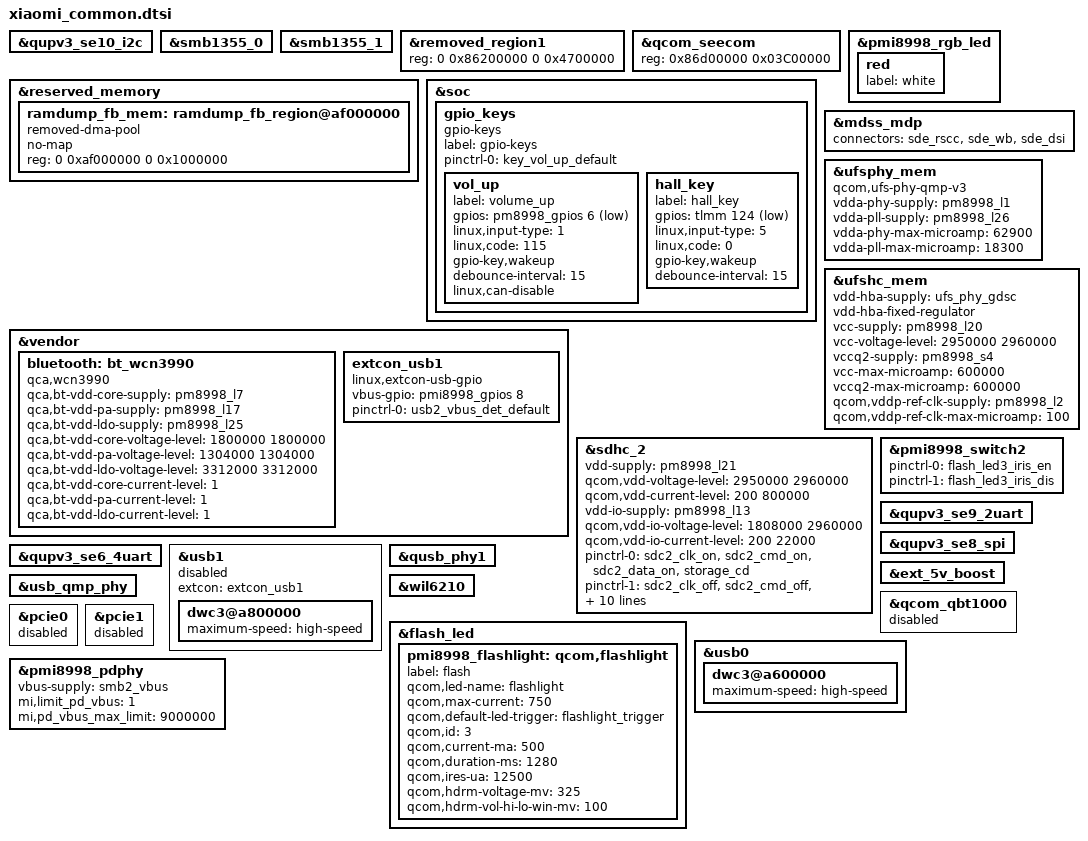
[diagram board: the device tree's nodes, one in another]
/*
 * Common nodes between xiaomi-sdm845 devices
 */

&qupv3_se10_i2c {
	#include "../../qcom/smb1355.dtsi"
};

&smb1355_0 {
	status = "okay";
};

&smb1355_1 {
	status = "okay";
};

&removed_region1 {
	reg = <0 0x86200000 0 0x4700000>;
};

&qcom_seecom {
	reg = <0x86d00000 0x03C00000>;
};

&reserved_memory {
	ramdump_fb_mem: ramdump_fb_region@af000000 {
		compatible = "removed-dma-pool";
		no-map;
		reg = <0 0xaf000000 0 0x1000000>;
	};
};

&soc {
	gpio_keys {
		compatible = "gpio-keys";
		label = "gpio-keys";

		pinctrl-names = "default";
		pinctrl-0 = <&key_vol_up_default>;

		vol_up {
			label = "volume_up";
			gpios = <&pm8998_gpios 6 GPIO_ACTIVE_LOW>;
			linux,input-type = <1>;
			linux,code = <115>;
			gpio-key,wakeup;
			debounce-interval = <15>;
			linux,can-disable;
		};

		hall_key {
			label = "hall_key";
			gpios = <&tlmm 124 GPIO_ACTIVE_LOW>;
			linux,input-type = <5>;
			linux,code = <0>;
			gpio-key,wakeup;
			debounce-interval = <15>;
		};
	};
};

&vendor {
	bluetooth: bt_wcn3990 {
		compatible = "qca,wcn3990";
		qca,bt-vdd-core-supply = <&pm8998_l7>;
		qca,bt-vdd-pa-supply = <&pm8998_l17>;
		qca,bt-vdd-ldo-supply = <&pm8998_l25>;

		qca,bt-vdd-core-voltage-level = <1800000 1800000>;
		qca,bt-vdd-pa-voltage-level = <1304000 1304000>;
		qca,bt-vdd-ldo-voltage-level = <3312000 3312000>;

		qca,bt-vdd-core-current-level = <1>; /* LPM/PFM */
		qca,bt-vdd-pa-current-level = <1>; /* LPM/PFM */
		qca,bt-vdd-ldo-current-level = <1>; /* LPM/PFM */
	};
};

&pmi8998_rgb_led {
	red {
		label = "white";
	};
	/delete-node/ green;
	/delete-node/ blue;
};

&mdss_mdp {
	#cooling-cells = <2>;
	connectors = <&sde_rscc &sde_wb &sde_dsi>;
};

&ufsphy_mem {
	compatible = "qcom,ufs-phy-qmp-v3";

	vdda-phy-supply = <&pm8998_l1>; /* 0.88v */
	vdda-pll-supply = <&pm8998_l26>; /* 1.2v */
	vdda-phy-max-microamp = <62900>;
	vdda-pll-max-microamp = <18300>;

	status = "ok";
};

&ufshc_mem {
	vdd-hba-supply = <&ufs_phy_gdsc>;
	vdd-hba-fixed-regulator;
	vcc-supply = <&pm8998_l20>;
	vcc-voltage-level = <2950000 2960000>;
	vccq2-supply = <&pm8998_s4>;
	vcc-max-microamp = <600000>;
	vccq2-max-microamp = <600000>;

	qcom,vddp-ref-clk-supply = <&pm8998_l2>;
	qcom,vddp-ref-clk-max-microamp = <100>;

	status = "ok";
};

&sdhc_2 {
	vdd-supply = <&pm8998_l21>;
	qcom,vdd-voltage-level = <2950000 2960000>;
	qcom,vdd-current-level = <200 800000>;

	vdd-io-supply = <&pm8998_l13>;
	qcom,vdd-io-voltage-level = <1808000 2960000>;
	qcom,vdd-io-current-level = <200 22000>;

	pinctrl-names = "active", "sleep", "ds_400KHz",
			"ds_50MHz", "ds_100MHz", "ds_200MHz";
	pinctrl-0 = <&sdc2_clk_on  &sdc2_cmd_on &sdc2_data_on &storage_cd>;
	pinctrl-1 = <&sdc2_clk_off &sdc2_cmd_off &sdc2_data_off &storage_cd>;
	pinctrl-2 = <&sdc2_clk_ds_400KHz
			&sdc2_cmd_ds_400KHz &sdc2_data_ds_400KHz>;
	pinctrl-3 = <&sdc2_clk_ds_50MHz
			&sdc2_cmd_ds_50MHz &sdc2_data_ds_50MHz>;
	pinctrl-4 = <&sdc2_clk_ds_100MHz
			&sdc2_cmd_ds_100MHz &sdc2_data_ds_100MHz>;
	pinctrl-5 = <&sdc2_clk_ds_200MHz
			&sdc2_cmd_ds_200MHz &sdc2_data_ds_200MHz>;

	cd-gpios = <&tlmm 126 GPIO_ACTIVE_LOW>;

	status = "ok";
};

&pmi8998_switch2 {
	pinctrl-names = "led_enable", "led_disable";
	pinctrl-0 = <&flash_led3_iris_en>;
	pinctrl-1 = <&flash_led3_iris_dis>;
};

&vendor {
	extcon_usb1: extcon_usb1 {
		compatible = "linux,extcon-usb-gpio";
		vbus-gpio = <&pmi8998_gpios 8 GPIO_ACTIVE_HIGH>;

		pinctrl-names = "default";
		pinctrl-0 = <&usb2_vbus_det_default>;
	};
};

&qupv3_se9_2uart {
	status = "ok";
};

&qupv3_se8_spi {
	status = "ok";
};

&qupv3_se6_4uart {
	status = "ok";
};

&usb1 {
	status = "disabled";
	extcon = <&extcon_usb1>;
};

&qusb_phy1 {
	status = "okay";
};

&ext_5v_boost {
	status = "ok";
};

&usb_qmp_phy {
	status = "okay";
};

&wil6210 {
	status = "ok";
};

&qcom_qbt1000 {
	status = "disabled";
};

&flash_led {
	pmi8998_flashlight: qcom,flashlight {
		label = "flash";
		qcom,led-name = "flashlight";
		qcom,max-current = <750>;
		qcom,default-led-trigger = "flashlight_trigger";
		qcom,id = <3>;
		qcom,current-ma = <500>;
		qcom,duration-ms = <1280>;
		qcom,ires-ua = <12500>;
		qcom,hdrm-voltage-mv = <325>;
		qcom,hdrm-vol-hi-lo-win-mv = <100>;
	};
};

#include "xiaomi_common_thermal.dtsi"

&usb0 {
	dwc3@a600000 {
		maximum-speed = "high-speed";
	};
};

&usb1 {
	dwc3@a800000 {
		maximum-speed = "high-speed";
	};
};

&pcie0 {
	status = "disabled";
};

&pcie1 {
	status = "disabled";
};

&pmi8998_pdphy {
	vbus-supply = <&smb2_vbus>;
	/*mi,limit_pd_vbus 1:enable 0:disable*/
	mi,limit_pd_vbus = <1>;
	mi,pd_vbus_max_limit = <9000000>;
};
